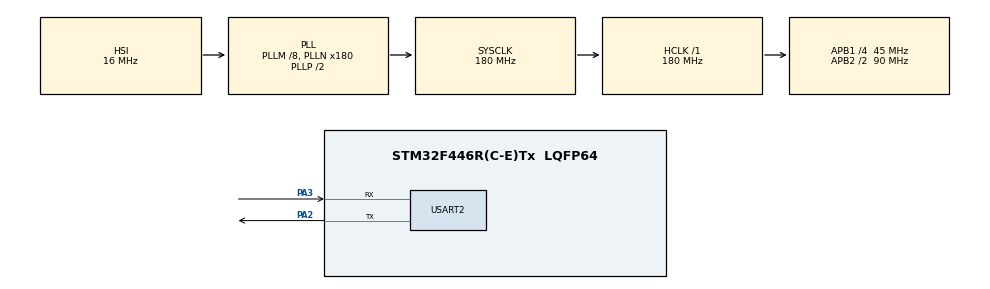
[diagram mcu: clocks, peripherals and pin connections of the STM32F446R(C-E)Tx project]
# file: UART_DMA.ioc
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Dma.Request0=USART2_RX
Dma.USART2_RX.0.Direction=DMA_PERIPH_TO_MEMORY
Dma.USART2_RX.0.FIFOMode=DMA_FIFOMODE_DISABLE
Dma.USART2_RX.0.Instance=DMA1_Stream5
Dma.USART2_RX.0.MemDataAlignment=DMA_MDATAALIGN_BYTE
Dma.USART2_RX.0.MemInc=DMA_MINC_ENABLE
Dma.USART2_RX.0.Mode=DMA_CIRCULAR
Dma.USART2_RX.0.PeriphDataAlignment=DMA_PDATAALIGN_BYTE
Dma.USART2_RX.0.PeriphInc=DMA_PINC_DISABLE
Dma.USART2_RX.0.Priority=DMA_PRIORITY_LOW
Mcu.Family=STM32F4
Mcu.Name=STM32F446R(C-E)Tx
Mcu.Package=LQFP64
NVIC.DMA1_Stream5_IRQn=true\:0\:0\:false\:false\:true\:false\:true\:true
NVIC.PriorityGroup=NVIC_PRIORITYGROUP_4
NVIC.USART2_IRQn=true\:0\:0\:false\:false\:true\:true\:true\:true
PA13.Mode=Serial_Wire
PA13.Signal=SYS_JTMS-SWDIO
PA14.Mode=Serial_Wire
PA14.Signal=SYS_JTCK-SWCLK
PA2.Mode=Asynchronous
PA2.Signal=USART2_TX
PA3.Mode=Asynchronous
PA3.Signal=USART2_RX
PH0-OSC_IN.Mode=HSE-External-Oscillator
PH0-OSC_IN.Signal=RCC_OSC_IN
PH1-OSC_OUT.Mode=HSE-External-Oscillator
PH1-OSC_OUT.Signal=RCC_OSC_OUT
ProjectManager.HeapSize=0x200
ProjectManager.StackSize=0x400
ProjectManager.TargetToolchain=STM32CubeIDE
RCC.AHBFreq_Value=180000000
RCC.APB1CLKDivider=RCC_HCLK_DIV4
RCC.APB1Freq_Value=45000000
RCC.APB1TimFreq_Value=90000000
RCC.APB2CLKDivider=RCC_HCLK_DIV2
RCC.APB2Freq_Value=90000000
RCC.APB2TimFreq_Value=180000000
RCC.CortexFreq_Value=180000000
RCC.HCLKFreq_Value=180000000
RCC.HSE_VALUE=8000000
RCC.PLLM=8
RCC.PLLN=180
RCC.SYSCLKFreq_VALUE=180000000
RCC.SYSCLKSource=RCC_SYSCLKSOURCE_PLLCLK
RCC.USBFreq_Value=180000000
RCC.VCOOutputFreq_Value=360000000
USART2.VirtualMode=VM_ASYNC
board=custom

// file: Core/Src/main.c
/* USER CODE BEGIN Header */
/**
  ******************************************************************************
  * @file           : main.c
  * @brief          : Main program body
  ******************************************************************************
  * @attention
  *
  * Copyright (c) 2023 STMicroelectronics.
  * All rights reserved.
  *
  * This software is licensed under terms that can be found in the LICENSE file
  * in the root directory of this software component.
  * If no LICENSE file comes with this software, it is provided AS-IS.
  *
  ******************************************************************************
  */
/* USER CODE END Header */
#include "main.h"

 UART_HandleTypeDef huart2;
DMA_HandleTypeDef hdma_usart2_rx;

void SystemClock_Config(void);
static void MX_GPIO_Init(void);
static void MX_DMA_Init(void);
static void MX_USART2_UART_Init(void);

/* USER CODE BEGIN 0 */
#define RX_BUFFER_SIZE		100

uint8_t aRXBufferUser[RX_BUFFER_SIZE];

uint8_t aRXBufferA[RX_BUFFER_SIZE];
uint8_t aRXBufferB[RX_BUFFER_SIZE];

uint8_t aTextInfoStart[] = "\r\nUSART Example : Enter characters to fill reception buffers.\r\n";

__IO uint32_t     uwNbReceivedChars;
uint8_t *pBufferReadyForUser;
uint8_t *pBufferReadyForReception;

void UserDataTreatment(UART_HandleTypeDef *huart, uint8_t* pData, uint16_t Size)
{
  uint8_t* pBuff = pData;

  HAL_UART_Transmit(huart, pBuff, Size, 100);
}
/* USER CODE END 0 */

int main(void)
{

  /* MCU Configuration--------------------------------------------------------*/

  /* Reset of all peripherals, Initializes the Flash interface and the Systick. */
  HAL_Init();

  /* Configure the system clock */
  SystemClock_Config();

  /* Initialize all configured peripherals */
  MX_GPIO_Init();
  MX_DMA_Init();
  MX_USART2_UART_Init();
  /* USER CODE BEGIN 2 */
  if (HAL_OK != HAL_UARTEx_ReceiveToIdle_DMA(&huart2, aRXBufferUser, RX_BUFFER_SIZE))
  {
	  Error_Handler();
  }

  pBufferReadyForReception = aRXBufferA;
  pBufferReadyForUser      = aRXBufferB;
  uwNbReceivedChars        = 0;

  HAL_UART_Transmit(&huart2, aTextInfoStart, sizeof(aTextInfoStart), 100);
  /* USER CODE END 2 */

  /* Infinite loop */
  while (1)
  {

  }
}

void SystemClock_Config(void)
{
  RCC_OscInitTypeDef RCC_OscInitStruct = {0};
  RCC_ClkInitTypeDef RCC_ClkInitStruct = {0};

  /** Configure the main internal regulator output voltage
  */
  __HAL_RCC_PWR_CLK_ENABLE();
  __HAL_PWR_VOLTAGESCALING_CONFIG(PWR_REGULATOR_VOLTAGE_SCALE1);

  /** Initializes the RCC Oscillators according to the specified parameters
  * in the RCC_OscInitTypeDef structure.
  */
  RCC_OscInitStruct.OscillatorType = RCC_OSCILLATORTYPE_HSI;
  RCC_OscInitStruct.HSIState = RCC_HSI_ON;
  RCC_OscInitStruct.HSICalibrationValue = RCC_HSICALIBRATION_DEFAULT;
  RCC_OscInitStruct.PLL.PLLState = RCC_PLL_ON;
  RCC_OscInitStruct.PLL.PLLSource = RCC_PLLSOURCE_HSI;
  RCC_OscInitStruct.PLL.PLLM = 8;
  RCC_OscInitStruct.PLL.PLLN = 180;
  RCC_OscInitStruct.PLL.PLLP = RCC_PLLP_DIV2;
  RCC_OscInitStruct.PLL.PLLQ = 2;
  RCC_OscInitStruct.PLL.PLLR = 2;
  if (HAL_RCC_OscConfig(&RCC_OscInitStruct) != HAL_OK)
  {
    Error_Handler();
  }

  /** Activate the Over-Drive mode
  */
  if (HAL_PWREx_EnableOverDrive() != HAL_OK)
  {
    Error_Handler();
  }

  /** Initializes the CPU, AHB and APB buses clocks
  */
  RCC_ClkInitStruct.ClockType = RCC_CLOCKTYPE_HCLK|RCC_CLOCKTYPE_SYSCLK
                              |RCC_CLOCKTYPE_PCLK1|RCC_CLOCKTYPE_PCLK2;
  RCC_ClkInitStruct.SYSCLKSource = RCC_SYSCLKSOURCE_PLLCLK;
  RCC_ClkInitStruct.AHBCLKDivider = RCC_SYSCLK_DIV1;
  RCC_ClkInitStruct.APB1CLKDivider = RCC_HCLK_DIV4;
  RCC_ClkInitStruct.APB2CLKDivider = RCC_HCLK_DIV2;

  if (HAL_RCC_ClockConfig(&RCC_ClkInitStruct, FLASH_LATENCY_5) != HAL_OK)
  {
    Error_Handler();
  }
}

static void MX_USART2_UART_Init(void)
{

  huart2.Instance = USART2;
  huart2.Init.BaudRate = 115200;
  huart2.Init.WordLength = UART_WORDLENGTH_8B;
  huart2.Init.StopBits = UART_STOPBITS_1;
  huart2.Init.Parity = UART_PARITY_NONE;
  huart2.Init.Mode = UART_MODE_TX_RX;
  huart2.Init.HwFlowCtl = UART_HWCONTROL_NONE;
  huart2.Init.OverSampling = UART_OVERSAMPLING_16;
  if (HAL_UART_Init(&huart2) != HAL_OK)
  {
    Error_Handler();
  }

}

static void MX_DMA_Init(void)
{

  /* DMA controller clock enable */
  __HAL_RCC_DMA1_CLK_ENABLE();

  /* DMA interrupt init */
  /* DMA1_Stream5_IRQn interrupt configuration */
  HAL_NVIC_SetPriority(DMA1_Stream5_IRQn, 0, 0);
  HAL_NVIC_EnableIRQ(DMA1_Stream5_IRQn);

}

static void MX_GPIO_Init(void)
{

  /* GPIO Ports Clock Enable */
  __HAL_RCC_GPIOH_CLK_ENABLE();
  __HAL_RCC_GPIOA_CLK_ENABLE();

}

/* USER CODE BEGIN 4 */
void HAL_UARTEx_RxEventCallback(UART_HandleTypeDef *huart, uint16_t Size)
{
  static uint16_t old_pos = 0;
  uint8_t *ptemp;
  uint16_t i;

  /* Check if number of received data in recpetion buffer has changed */
  if (Size != old_pos)
  {
    /* Check if position of index in reception buffer has simply be increased
       of if end of buffer has been reached */
    if (Size > old_pos)
    {
      /* Current position is higher than previous one */
      uwNbReceivedChars = Size - old_pos;
      /* Copy received data in "User" buffer for evacuation */
      for (i = 0; i < uwNbReceivedChars; i++)
      {
        pBufferReadyForUser[i] = aRXBufferUser[old_pos + i];
      }
    }
    else
    {
      /* Current position is lower than previous one : end of buffer has been reached */
      /* First copy data from current position till end of buffer */
      uwNbReceivedChars = RX_BUFFER_SIZE - old_pos;
      /* Copy received data in "User" buffer for evacuation */
      for (i = 0; i < uwNbReceivedChars; i++)
      {
        pBufferReadyForUser[i] = aRXBufferUser[old_pos + i];
      }
      /* Check and continue with beginning of buffer */
      if (Size > 0)
      {
        for (i = 0; i < Size; i++)
        {
          pBufferReadyForUser[uwNbReceivedChars + i] = aRXBufferUser[i];
        }
        uwNbReceivedChars += Size;
      }
    }
    /* Process received data that has been extracted from Rx User buffer */
    UserDataTreatment(huart, pBufferReadyForUser, uwNbReceivedChars);

    /* Swap buffers for next bytes to be processed */
    ptemp = pBufferReadyForUser;
    pBufferReadyForUser = pBufferReadyForReception;
    pBufferReadyForReception = ptemp;
  }
  /* Update old_pos as new reference of position in User Rx buffer that indicates position to which data have been processed */
  old_pos = Size;

}
/* USER CODE END 4 */

void Error_Handler(void)
{
  __disable_irq();
  while (1)
  {
  }
}
